# DA14531 register map
Vendor: Dialog; Series: DA14531; File version: 1.2
CPU: CM0 r1p0, little endian, MPU, FPU, 3 interrupt priority bits
Registers are 16-bit, read-write, reset 0x0 unless marked. A register's access mark holds for its fields unless they carry their own. Offsets are from the block's base; [hi:lo] are bit positions; 'fields as' and 'values as' point back to an identical list.

## SysTick — Cortex M0 SysTick registers
Base 0xE000E010
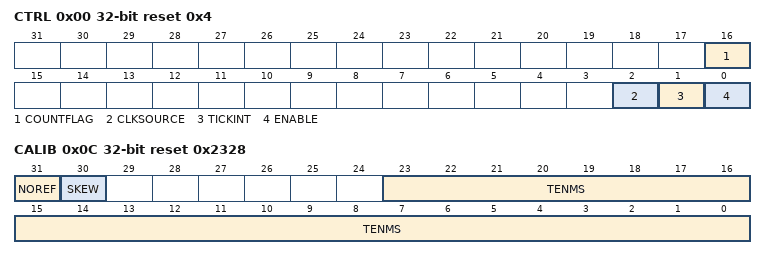
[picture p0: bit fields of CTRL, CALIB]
0x00 CTRL 32-bit reset 0x4 — SysTick Control and Status register
  [16] COUNTFLAG — Timer counted to 0 since last time this was read
  [2] CLKSOURCE — Clock source selection
  [1] TICKINT — SysTick exception request enable
  [0] ENABLE — SysTick Counter enable
0x04 LOAD 32-bit — SysTick Reload value register
  [23:0] RELOAD — RELOAD[23:0] bits (Reload value)
0x08 VAL 32-bit — SysTick Current value register
  [23:0] CURRENT — CURRENT[23:0] bits (Current counter value)
0x0C CALIB 32-bit ro reset 0x2328 — SysTick Calibration value register
  [31] NOREF — Indicates that a separate reference clock is provided
  [30] SKEW — Indicates whether the TENMS value is exact
  [23:0] TENMS — TENMS[23:0] bits (Calibration value)

## ANAMISC — ANAMISC registers
Base 0x50001600
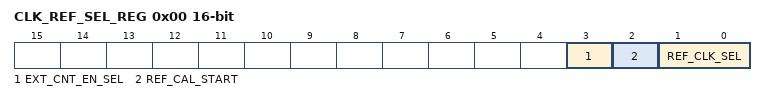
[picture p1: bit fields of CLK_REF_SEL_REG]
0x00 CLK_REF_SEL_REG — Select clock for oscillator calibration
  [3] EXT_CNT_EN_SEL — 0 : Enable XTAL_CNT counter by the REF_CLK selected by REF_CLK_SEL. 1 : Enable XTAL_CNT counter from an external input.
  [2] REF_CAL_START — Writing a '1' starts a calibration of the clock selected by CLK_REF_SEL_REG[REF_CLK_SEL]. This bit is cleared when calibration is finished, and CLK_REF_VAL is ready.
  [1:0] REF_CLK_SEL — Select clock input for calibration: 0x0 : RC32K 0x1 : RC32M 0x2 : XTAL32K 0x3 : RCX
0x02 CLK_REF_CNT_REG — Count value for oscillator calibration
  [15:0] REF_CNT_VAL — Indicates the calibration time, with a decrement counter to 1.
0x04 CLK_REF_VAL_L_REG — XTAL32M reference cycles, lower 16 bits
  [15:0] XTAL_CNT_VAL ro — Returns the number of DIVN clock cycles counted during the calibration time, defined with REF_CNT_VAL
0x06 CLK_REF_VAL_H_REG — XTAL32M reference cycles, higher 16 bits
  fields as CLK_REF_VAL_L_REG

## CHIP_VERSION — CHIP_VERSION registers
Base 0x50003200
0x00 CHIP_ID1_REG reset 0x32 — Chip identification register 1.
  [7:0] CHIP_ID1 ro — First character of device type "2632" in ASCII.
0x04 CHIP_ID2_REG reset 0x36 — Chip identification register 2.
  [7:0] CHIP_ID2 ro — Second character of device type "2632" in ASCII.
0x08 CHIP_ID3_REG reset 0x33 — Chip identification register 3.
  [7:0] CHIP_ID3 ro — Third character of device type "2632" in ASCII.
0x0C CHIP_ID4_REG reset 0x32 — Chip identification register 4.
  [7:0] CHIP_ID4 ro — Fourth character of device type "2632" in ASCII.
0x10 CHIP_SWC_REG
  [3:0] CHIP_SWC ro
0x14 CHIP_REVISION_REG reset 0x41
  [7:0] CHIP_REVISION ro
0xF8 CHIP_TEST1_REG reset 0x41
  [7:0] CHIP_LAYOUT_REVISION ro
0xFC CHIP_TEST2_REG
  [3:0] CHIP_METAL_OPTION ro

## CRG_AON — CRG_AON registers
Base 0x50000300
0x00 HWR_CTRL_REG — Hardware Reset control register
  [0] DISABLE_HWR — Disables the RST functionality on P00
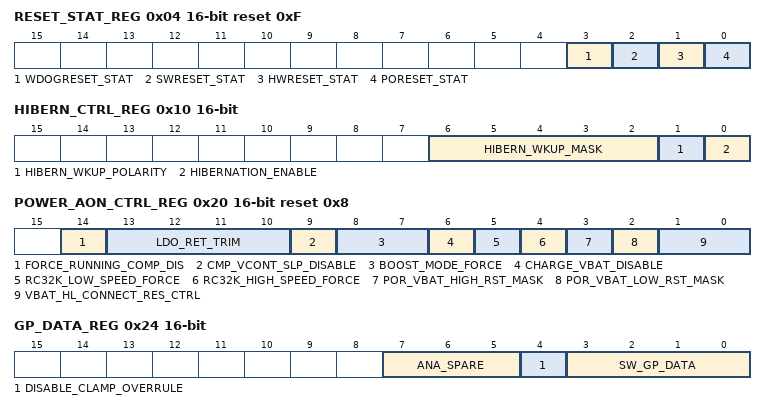
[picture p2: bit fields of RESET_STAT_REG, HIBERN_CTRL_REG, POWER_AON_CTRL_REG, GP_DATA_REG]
0x04 RESET_STAT_REG reset 0xF — Reset status register
  [3] WDOGRESET_STAT — Indicates that a Watchdog has happened. This bit is also set with a PowerOn Reset
  [2] SWRESET_STAT — Indicates that a SW Reset has been requested. The SW reset is requested by SYS_CTRL_REG[SW_RESET] or SCB->AIRCR inside the ARM. This bit is also set with a PowerOn Reset
  [1] HWRESET_STAT — Indicates that a HW Reset has happened This bit is also set with a PowerOn Reset
  [0] PORESET_STAT — Indicates that a PowerOn Reset has happened
0x08 RAM_LPMX_REG reset 0x7
  [2:0] RAMx_LPMX — RAM[3:1] Transparent Light Sleep (TLS) Core Enable for System RAMs. Assert low to enable the TLS core feature, which will result in lower leakage current. In case VDD is below 0.81V, it is necessary to hold this pin high to maintain data retention.
0x0C PAD_LATCH_REG reset 0x1 — Control the state retention of the GPIO ports
  [0] PAD_LATCH_EN — Controls the state retention of the pads. 0: latches are closed, pads retain their state. 1: latches are open, new control values have immediate effect
0x10 HIBERN_CTRL_REG — Hibernation control register
  [6:2] HIBERN_WKUP_MASK — Selects which pin to wakeup from
  [1] HIBERN_WKUP_POLARITY — Selects the polarity of the wakeup source. The polarity must be chosen such that the ANA_STATUS_REG[CLKLESS_WAKEUP_STAT] is '1'. Any change on the selected GPIOs will make the CLKLESS_WAKEUP_STAT go to '0', and wakeup the system from hibernation.
  [0] HIBERNATION_ENABLE — Enables the hibernation mode when sleeping 0: deep sleep mode, PD_SLP remains on 1: hibernation mode, PD_SLP goes off. REMAP_ADR0 needs to be set to the correct source to boot from before going to sleep.
0x20 POWER_AON_CTRL_REG reset 0x8
  [14] FORCE_RUNNING_COMP_DIS
  [13:10] LDO_RET_TRIM — VDD clamp level setting for hibernation mode
  [9] CMP_VCONT_SLP_DISABLE — Disable vcont comparator in SLP
  [8:7] BOOST_MODE_FORCE — 0x:automatic selection of boost mode 11: force boost mode 10: force buck mode
  [6] CHARGE_VBAT_DISABLE — Do not charge vbat high in boost mode
  [5] RC32K_LOW_SPEED_FORCE
  [4] RC32K_HIGH_SPEED_FORCE
  [3] POR_VBAT_HIGH_RST_MASK — Mask rst from por_vbat_high
  [2] POR_VBAT_LOW_RST_MASK — Mask rst from por_vbat_low
  [1:0] VBAT_HL_CONNECT_RES_CTRL — 00: OFF 01: Forced ON 10: Active: automatic control, Sleep: forced ON 11: Automatic control
0x24 GP_DATA_REG
  [7:5] ANA_SPARE, [4] DISABLE_CLAMP_OVERRULE, [3:0] SW_GP_DATA
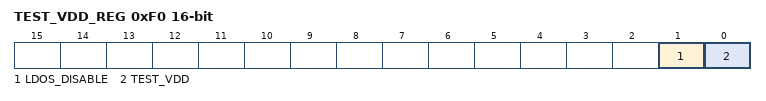
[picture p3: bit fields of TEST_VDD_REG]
0xF0 TEST_VDD_REG
  [1] LDOS_DISABLE, [0] TEST_VDD
